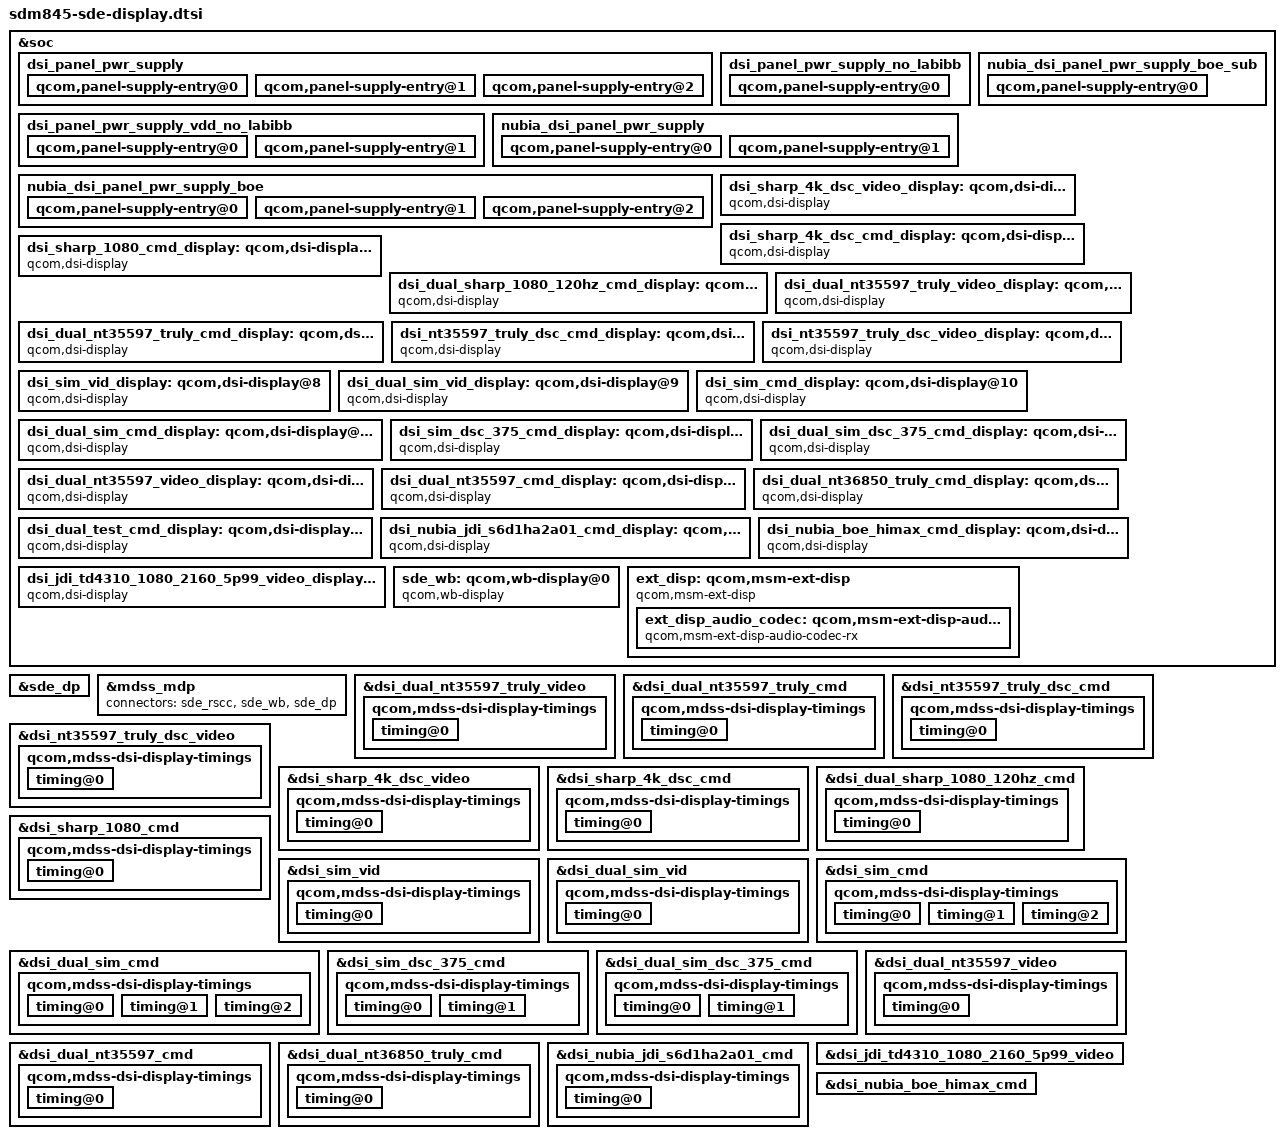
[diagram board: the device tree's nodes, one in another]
/* Copyright (c) 2016-2018, The Linux Foundation. All rights reserved.
 *
 * This program is free software; you can redistribute it and/or modify
 * it under the terms of the GNU General Public License version 2 and
 * only version 2 as published by the Free Software Foundation.
 *
 * This program is distributed in the hope that it will be useful,
 * but WITHOUT ANY WARRANTY; without even the implied warranty of
 * MERCHANTABILITY or FITNESS FOR A PARTICULAR PURPOSE.  See the
 * GNU General Public License for more details.
 */

#include "dsi-panel-sim-video.dtsi"
#include "dsi-panel-sim-cmd.dtsi"
#include "dsi-panel-sim-dsc375-cmd.dtsi"
#include "dsi-panel-sim-dualmipi-video.dtsi"
#include "dsi-panel-sim-dualmipi-cmd.dtsi"
#include "dsi-panel-sim-dualmipi-dsc375-cmd.dtsi"
#include "dsi-panel-sharp-dsc-4k-video.dtsi"
#include "dsi-panel-sharp-dsc-4k-cmd.dtsi"
#include "dsi-panel-nt35597-truly-dualmipi-wqxga-video.dtsi"
#include "dsi-panel-nt35597-truly-dualmipi-wqxga-cmd.dtsi"
#include "dsi-panel-nt35597-truly-dsc-wqxga-cmd.dtsi"
#include "dsi-panel-nt35597-truly-dsc-wqxga-video.dtsi"
#include "dsi-panel-sharp-1080p-cmd.dtsi"
#include "dsi-panel-sharp-dualmipi-1080p-120hz.dtsi"
#include "dsi-panel-s6e3ha3-amoled-dualmipi-wqhd-cmd.dtsi"
#include "dsi-panel-nt35597-dualmipi-wqxga-video.dtsi"
#include "dsi-panel-nt35597-dualmipi-wqxga-cmd.dtsi"
#include "dsi-panel-nt36850-truly-dualmipi-wqhd-cmd.dtsi"
#include "dsi-panel-test-dualmipi-oled-cmd.dtsi"
#include <dt-bindings/clock/mdss-10nm-pll-clk.h>
#include "../nubia/NX616J/dsi-panel-s6d1ha2a01-jdi-1080x2160-cmd.dtsi"
#include "../nubia/NX616J/dsi-panel-himax-boe-1080x2280-cmd.dtsi"
#include "../nubia/NX616J/nubia-jdi-td4310-1080-2160-5p99-video.dtsi"
&soc {
	dsi_panel_pwr_supply: dsi_panel_pwr_supply {
		#address-cells = <1>;
		#size-cells = <0>;

		qcom,panel-supply-entry@0 {
			reg = <0>;
			qcom,supply-name = "vddio";
			qcom,supply-min-voltage = <1800000>;
			qcom,supply-max-voltage = <1800000>;
			qcom,supply-enable-load = <62000>;
			qcom,supply-disable-load = <80>;
			qcom,supply-post-on-sleep = <20>;
		};

		qcom,panel-supply-entry@1 {
			reg = <1>;
			qcom,supply-name = "lab";
			qcom,supply-min-voltage = <4600000>;
			qcom,supply-max-voltage = <6000000>;
			qcom,supply-enable-load = <100000>;
			qcom,supply-disable-load = <100>;
		};

		qcom,panel-supply-entry@2 {
			reg = <2>;
			qcom,supply-name = "ibb";
			qcom,supply-min-voltage = <4600000>;
			qcom,supply-max-voltage = <6000000>;
			qcom,supply-enable-load = <100000>;
			qcom,supply-disable-load = <100>;
			qcom,supply-post-on-sleep = <20>;
		};
	};

	dsi_panel_pwr_supply_no_labibb: dsi_panel_pwr_supply_no_labibb {
		#address-cells = <1>;
		#size-cells = <0>;

		qcom,panel-supply-entry@0 {
			reg = <0>;
			qcom,supply-name = "vddio";
			qcom,supply-min-voltage = <1800000>;
			qcom,supply-max-voltage = <1800000>;
			qcom,supply-enable-load = <62000>;
			qcom,supply-disable-load = <80>;
			qcom,supply-post-on-sleep = <20>;
		};
	};

	dsi_panel_pwr_supply_vdd_no_labibb: dsi_panel_pwr_supply_vdd_no_labibb {
		#address-cells = <1>;
		#size-cells = <0>;

		qcom,panel-supply-entry@0 {
			reg = <0>;
			qcom,supply-name = "vddio";
			qcom,supply-min-voltage = <1800000>;
			qcom,supply-max-voltage = <1800000>;
			qcom,supply-enable-load = <62000>;
			qcom,supply-disable-load = <80>;
			qcom,supply-post-on-sleep = <20>;
		};

		qcom,panel-supply-entry@1 {
			reg = <1>;
			qcom,supply-name = "vdd";
			qcom,supply-min-voltage = <3000000>;
			qcom,supply-max-voltage = <3000000>;
			qcom,supply-enable-load = <857000>;
			qcom,supply-disable-load = <0>;
			qcom,supply-post-on-sleep = <0>;
		};
	};

	nubia_dsi_panel_pwr_supply: nubia_dsi_panel_pwr_supply {
			#address-cells = <1>;
			#size-cells = <0>;

			qcom,panel-supply-entry@0 {
				reg = <0>;
				qcom,supply-name = "lab";
				qcom,supply-min-voltage = <5400000>;
				qcom,supply-max-voltage = <5600000>;
				qcom,supply-enable-load = <100000>;
				qcom,supply-disable-load = <100>;
			};
			qcom,panel-supply-entry@1 {
				reg = <1>;
				qcom,supply-name = "ibb";
				qcom,supply-min-voltage = <5400000>;
				qcom,supply-max-voltage = <5600000>;
				qcom,supply-enable-load = <100000>;
				qcom,supply-disable-load = <100>;
			};
		};
//start :add the power of lcds for NX616J -------0330
	nubia_dsi_panel_pwr_supply_boe: nubia_dsi_panel_pwr_supply_boe {
			#address-cells = <1>;
			#size-cells = <0>;
		qcom,panel-supply-entry@0 {
			reg = <0>;
			qcom,supply-name = "vddio";
			qcom,supply-min-voltage = <1800000>;
			qcom,supply-max-voltage = <1800000>;
			qcom,supply-enable-load = <62000>;
			qcom,supply-disable-load = <80>;
			qcom,supply-post-on-sleep = <20>;
		};			
			qcom,panel-supply-entry@1 {
				reg = <1>;
				qcom,supply-name = "lab";
				qcom,supply-min-voltage = <5400000>;
				qcom,supply-max-voltage = <5600000>;
				qcom,supply-enable-load = <100000>;
				qcom,supply-disable-load = <100>;
			};
			qcom,panel-supply-entry@2 {
				reg = <2>;
				qcom,supply-name = "ibb";
				qcom,supply-min-voltage = <5400000>;
				qcom,supply-max-voltage = <5600000>;
				qcom,supply-enable-load = <100000>;
				qcom,supply-disable-load = <100>;
			};
		/*	
			qcom,panel-supply-entry@3 {
				reg = <3>;
				qcom,supply-name = "sub_lcd";
				qcom,supply-min-voltage = <3000000>;
				qcom,supply-max-voltage = <3000000>;
				qcom,supply-enable-load = <100000>;
				qcom,supply-disable-load = <100>;
			};*/
		};



	nubia_dsi_panel_pwr_supply_boe_sub: nubia_dsi_panel_pwr_supply_boe_sub {
			#address-cells = <1>;
			#size-cells = <0>;
			qcom,panel-supply-entry@0 {
				reg = <0>;
				qcom,supply-name = "sub_lcd";
				qcom,supply-min-voltage = <3000000>;
				qcom,supply-max-voltage = <3000000>;
				qcom,supply-enable-load = <100000>;
				qcom,supply-disable-load = <100>;
			};
		};
//End :add the power of lcds for NX616J -------0330

	dsi_sharp_4k_dsc_video_display: qcom,dsi-display@0 {
		compatible = "qcom,dsi-display";
		label = "dsi_sharp_4k_dsc_video_display";
		qcom,display-type = "primary";

		qcom,dsi-ctrl = <&mdss_dsi0 &mdss_dsi1>;
		qcom,dsi-phy = <&mdss_dsi_phy0 &mdss_dsi_phy1>;
		clocks = <&mdss_dsi0_pll BYTECLK_MUX_0_CLK>,
			<&mdss_dsi0_pll PCLK_MUX_0_CLK>;
		clock-names = "src_byte_clk", "src_pixel_clk";

		pinctrl-names = "panel_active", "panel_suspend";
		pinctrl-0 = <&sde_dsi_active &sde_te_active>;
		pinctrl-1 = <&sde_dsi_suspend &sde_te_suspend>;
		qcom,platform-te-gpio = <&tlmm 10 0>;
		qcom,platform-reset-gpio = <&tlmm 6 0>;
		qcom,panel-mode-gpio = <&tlmm 52 0>;

		qcom,dsi-panel = <&dsi_sharp_4k_dsc_video>;
		vddio-supply = <&pm8998_l14>;
		lab-supply = <&lab_regulator>;
		ibb-supply = <&ibb_regulator>;
	};

	dsi_sharp_4k_dsc_cmd_display: qcom,dsi-display@1 {
		compatible = "qcom,dsi-display";
		label = "dsi_sharp_4k_dsc_cmd_display";
		qcom,display-type = "primary";

		qcom,dsi-ctrl = <&mdss_dsi0 &mdss_dsi1>;
		qcom,dsi-phy = <&mdss_dsi_phy0 &mdss_dsi_phy1>;
		clocks = <&mdss_dsi0_pll BYTECLK_MUX_0_CLK>,
			<&mdss_dsi0_pll PCLK_MUX_0_CLK>;
		clock-names = "src_byte_clk", "src_pixel_clk";

		pinctrl-names = "panel_active", "panel_suspend";
		pinctrl-0 = <&sde_dsi_active &sde_te_active>;
		pinctrl-1 = <&sde_dsi_suspend &sde_te_suspend>;
		qcom,platform-te-gpio = <&tlmm 10 0>;
		qcom,platform-reset-gpio = <&tlmm 6 0>;
		qcom,panel-mode-gpio = <&tlmm 52 0>;

		qcom,dsi-panel = <&dsi_sharp_4k_dsc_cmd>;
		vddio-supply = <&pm8998_l14>;
		lab-supply = <&lab_regulator>;
		ibb-supply = <&ibb_regulator>;
	};

	dsi_sharp_1080_cmd_display: qcom,dsi-display@2 {
		compatible = "qcom,dsi-display";
		label = "dsi_sharp_1080_cmd_display";
		qcom,display-type = "primary";

		qcom,dsi-ctrl = <&mdss_dsi0>;
		qcom,dsi-phy = <&mdss_dsi_phy0>;
		clocks = <&mdss_dsi0_pll BYTECLK_MUX_0_CLK>,
			<&mdss_dsi0_pll PCLK_MUX_0_CLK>;
		clock-names = "src_byte_clk", "src_pixel_clk";

		pinctrl-names = "panel_active", "panel_suspend";
		pinctrl-0 = <&sde_dsi_active &sde_te_active>;
		pinctrl-1 = <&sde_dsi_suspend &sde_te_suspend>;
		qcom,platform-te-gpio = <&tlmm 10 0>;
		qcom,platform-reset-gpio = <&tlmm 6 0>;
		qcom,panel-mode-gpio = <&tlmm 52 0>;

		qcom,dsi-panel = <&dsi_sharp_1080_cmd>;
		vddio-supply = <&pm8998_l14>;
		lab-supply = <&lab_regulator>;
		ibb-supply = <&ibb_regulator>;
	};

	dsi_dual_sharp_1080_120hz_cmd_display: qcom,dsi-display@3 {
		compatible = "qcom,dsi-display";
		label = "dsi_dual_sharp_1080_120hz_cmd_display";
		qcom,display-type = "primary";

		qcom,dsi-ctrl = <&mdss_dsi0 &mdss_dsi1>;
		qcom,dsi-phy = <&mdss_dsi_phy0 &mdss_dsi_phy1>;
		clocks = <&mdss_dsi0_pll BYTECLK_MUX_0_CLK>,
			<&mdss_dsi0_pll PCLK_MUX_0_CLK>;
		clock-names = "src_byte_clk", "src_pixel_clk";

		pinctrl-names = "panel_active", "panel_suspend";
		pinctrl-0 = <&sde_dsi_active &sde_te_active>;
		pinctrl-1 = <&sde_dsi_suspend &sde_te_suspend>;
		qcom,platform-te-gpio = <&tlmm 10 0>;
		qcom,platform-reset-gpio = <&tlmm 6 0>;
		qcom,panel-mode-gpio = <&tlmm 52 0>;

		qcom,dsi-panel = <&dsi_dual_sharp_1080_120hz_cmd>;
		vddio-supply = <&pm8998_l14>;
		lab-supply = <&lab_regulator>;
		ibb-supply = <&ibb_regulator>;
	};

	dsi_dual_nt35597_truly_video_display: qcom,dsi-display@4 {
		compatible = "qcom,dsi-display";
		label = "dsi_dual_nt35597_truly_video_display";
		qcom,display-type = "primary";

		qcom,dsi-ctrl = <&mdss_dsi0 &mdss_dsi1>;
		qcom,dsi-phy = <&mdss_dsi_phy0 &mdss_dsi_phy1>;
		clocks = <&mdss_dsi0_pll BYTECLK_MUX_0_CLK>,
			<&mdss_dsi0_pll PCLK_MUX_0_CLK>;
		clock-names = "src_byte_clk", "src_pixel_clk";

		pinctrl-names = "panel_active", "panel_suspend";
		pinctrl-0 = <&sde_dsi_active &sde_te_active>;
		pinctrl-1 = <&sde_dsi_suspend &sde_te_suspend>;
		qcom,platform-reset-gpio = <&tlmm 6 0>;
		qcom,panel-mode-gpio = <&tlmm 52 0>;

		qcom,dsi-panel = <&dsi_dual_nt35597_truly_video>;
		vddio-supply = <&pm8998_l14>;
		lab-supply = <&lab_regulator>;
		ibb-supply = <&ibb_regulator>;
	};

	dsi_dual_nt35597_truly_cmd_display: qcom,dsi-display@5 {
		compatible = "qcom,dsi-display";
		label = "dsi_dual_nt35597_truly_cmd_display";
		qcom,display-type = "primary";

		qcom,dsi-ctrl = <&mdss_dsi0 &mdss_dsi1>;
		qcom,dsi-phy = <&mdss_dsi_phy0 &mdss_dsi_phy1>;
		clocks = <&mdss_dsi0_pll BYTECLK_MUX_0_CLK>,
			<&mdss_dsi0_pll PCLK_MUX_0_CLK>;
		clock-names = "src_byte_clk", "src_pixel_clk";

		pinctrl-names = "panel_active", "panel_suspend";
		pinctrl-0 = <&sde_dsi_active &sde_te_active>;
		pinctrl-1 = <&sde_dsi_suspend &sde_te_suspend>;
		qcom,platform-te-gpio = <&tlmm 10 0>;
		qcom,platform-reset-gpio = <&tlmm 6 0>;
		qcom,panel-mode-gpio = <&tlmm 52 0>;

		qcom,dsi-panel = <&dsi_dual_nt35597_truly_cmd>;
		vddio-supply = <&pm8998_l14>;
		lab-supply = <&lab_regulator>;
		ibb-supply = <&ibb_regulator>;
	};

	dsi_nt35597_truly_dsc_cmd_display: qcom,dsi-display@6 {
		compatible = "qcom,dsi-display";
		label = "dsi_nt35597_truly_dsc_cmd_display";
		qcom,display-type = "primary";

		qcom,dsi-ctrl = <&mdss_dsi1>;
		qcom,dsi-phy = <&mdss_dsi_phy1>;
		clocks = <&mdss_dsi1_pll BYTECLK_MUX_1_CLK>,
			<&mdss_dsi1_pll PCLK_MUX_1_CLK>;
		clock-names = "src_byte_clk", "src_pixel_clk";

		pinctrl-names = "panel_active", "panel_suspend";
		pinctrl-0 = <&sde_dsi_active &sde_te_active>;
		pinctrl-1 = <&sde_dsi_suspend &sde_te_suspend>;
		qcom,platform-te-gpio = <&tlmm 10 0>;
		qcom,platform-reset-gpio = <&tlmm 6 0>;
		qcom,panel-mode-gpio = <&tlmm 52 0>;

		qcom,dsi-panel = <&dsi_nt35597_truly_dsc_cmd>;
		vddio-supply = <&pm8998_l14>;
		lab-supply = <&lab_regulator>;
		ibb-supply = <&ibb_regulator>;
	};

	dsi_nt35597_truly_dsc_video_display: qcom,dsi-display@7 {
		compatible = "qcom,dsi-display";
		label = "dsi_nt35597_truly_dsc_video_display";
		qcom,display-type = "primary";

		qcom,dsi-ctrl = <&mdss_dsi1>;
		qcom,dsi-phy = <&mdss_dsi_phy1>;
		clocks = <&mdss_dsi1_pll BYTECLK_MUX_1_CLK>,
			<&mdss_dsi1_pll PCLK_MUX_1_CLK>;
		clock-names = "src_byte_clk", "src_pixel_clk";

		pinctrl-names = "panel_active", "panel_suspend";
		pinctrl-0 = <&sde_dsi_active &sde_te_active>;
		pinctrl-1 = <&sde_dsi_suspend &sde_te_suspend>;
		qcom,platform-te-gpio = <&tlmm 10 0>;
		qcom,platform-reset-gpio = <&tlmm 6 0>;
		qcom,panel-mode-gpio = <&tlmm 52 0>;

		qcom,dsi-panel = <&dsi_nt35597_truly_dsc_video>;
		vddio-supply = <&pm8998_l14>;
		lab-supply = <&lab_regulator>;
		ibb-supply = <&ibb_regulator>;
	};

	dsi_sim_vid_display: qcom,dsi-display@8 {
		compatible = "qcom,dsi-display";
		label = "dsi_sim_vid_display";
		qcom,display-type = "primary";

		qcom,dsi-ctrl = <&mdss_dsi0>;
		qcom,dsi-phy = <&mdss_dsi_phy0>;
		clocks = <&mdss_dsi0_pll BYTECLK_MUX_0_CLK>,
			<&mdss_dsi0_pll PCLK_MUX_0_CLK>;
		clock-names = "src_byte_clk", "src_pixel_clk";

		pinctrl-names = "panel_active", "panel_suspend";
		pinctrl-0 = <&sde_dsi_active &sde_te_active>;
		pinctrl-1 = <&sde_dsi_suspend &sde_te_suspend>;

		qcom,dsi-panel = <&dsi_sim_vid>;
	};

	dsi_dual_sim_vid_display: qcom,dsi-display@9 {
		compatible = "qcom,dsi-display";
		label = "dsi_dual_sim_vid_display";
		qcom,display-type = "primary";

		qcom,dsi-ctrl = <&mdss_dsi0 &mdss_dsi1>;
		qcom,dsi-phy = <&mdss_dsi_phy0 &mdss_dsi_phy1>;
		clocks = <&mdss_dsi0_pll BYTECLK_MUX_0_CLK>,
			<&mdss_dsi0_pll PCLK_MUX_0_CLK>;
		clock-names = "src_byte_clk", "src_pixel_clk";

		pinctrl-names = "panel_active", "panel_suspend";
		pinctrl-0 = <&sde_dsi_active &sde_te_active>;
		pinctrl-1 = <&sde_dsi_suspend &sde_te_suspend>;

		qcom,dsi-panel = <&dsi_dual_sim_vid>;
	};

	dsi_sim_cmd_display: qcom,dsi-display@10 {
		compatible = "qcom,dsi-display";
		label = "dsi_sim_cmd_display";
		qcom,display-type = "primary";

		qcom,dsi-ctrl = <&mdss_dsi0>;
		qcom,dsi-phy = <&mdss_dsi_phy0>;
		clocks = <&mdss_dsi0_pll BYTECLK_MUX_0_CLK>,
			<&mdss_dsi0_pll PCLK_MUX_0_CLK>;
		clock-names = "src_byte_clk", "src_pixel_clk";

		pinctrl-names = "panel_active", "panel_suspend";
		pinctrl-0 = <&sde_dsi_active &sde_te_active>;
		pinctrl-1 = <&sde_dsi_suspend &sde_te_suspend>;

		qcom,dsi-panel = <&dsi_sim_cmd>;
	};

	dsi_dual_sim_cmd_display: qcom,dsi-display@11 {
		compatible = "qcom,dsi-display";
		label = "dsi_dual_sim_cmd_display";
		qcom,display-type = "primary";

		qcom,dsi-ctrl = <&mdss_dsi0 &mdss_dsi1>;
		qcom,dsi-phy = <&mdss_dsi_phy0 &mdss_dsi_phy1>;
		clocks = <&mdss_dsi0_pll BYTECLK_MUX_0_CLK>,
			<&mdss_dsi0_pll PCLK_MUX_0_CLK>;
		clock-names = "src_byte_clk", "src_pixel_clk";

		pinctrl-names = "panel_active", "panel_suspend";
		pinctrl-0 = <&sde_dsi_active &sde_te_active>;
		pinctrl-1 = <&sde_dsi_suspend &sde_te_suspend>;

		qcom,dsi-panel = <&dsi_dual_sim_cmd>;
	};

	dsi_sim_dsc_375_cmd_display: qcom,dsi-display@12 {
		compatible = "qcom,dsi-display";
		label = "dsi_sim_dsc_375_cmd_display";
		qcom,display-type = "primary";

		qcom,dsi-ctrl = <&mdss_dsi0>;
		qcom,dsi-phy = <&mdss_dsi_phy0>;
		clocks = <&mdss_dsi0_pll BYTECLK_MUX_0_CLK>,
			<&mdss_dsi0_pll PCLK_MUX_0_CLK>;
		clock-names = "src_byte_clk", "src_pixel_clk";

		pinctrl-names = "panel_active", "panel_suspend";
		pinctrl-0 = <&sde_dsi_active &sde_te_active>;
		pinctrl-1 = <&sde_dsi_suspend &sde_te_suspend>;

		qcom,dsi-panel = <&dsi_sim_dsc_375_cmd>;
	};

	dsi_dual_sim_dsc_375_cmd_display: qcom,dsi-display@13 {
		compatible = "qcom,dsi-display";
		label = "dsi_dual_sim_dsc_375_cmd_display";
		qcom,display-type = "primary";

		qcom,dsi-ctrl = <&mdss_dsi0 &mdss_dsi1>;
		qcom,dsi-phy = <&mdss_dsi_phy0 &mdss_dsi_phy1>;
		clocks = <&mdss_dsi0_pll BYTECLK_MUX_0_CLK>,
			<&mdss_dsi0_pll PCLK_MUX_0_CLK>;
		clock-names = "src_byte_clk", "src_pixel_clk";

		pinctrl-names = "panel_active", "panel_suspend";
		pinctrl-0 = <&sde_dsi_active &sde_te_active>;
		pinctrl-1 = <&sde_dsi_suspend &sde_te_suspend>;

		qcom,dsi-panel = <&dsi_dual_sim_dsc_375_cmd>;
	};

	dsi_dual_nt35597_video_display: qcom,dsi-display@14 {
		compatible = "qcom,dsi-display";
		label = "dsi_dual_nt35597_video_display";
		qcom,display-type = "primary";

		qcom,dsi-ctrl = <&mdss_dsi0 &mdss_dsi1>;
		qcom,dsi-phy = <&mdss_dsi_phy0 &mdss_dsi_phy1>;
		clocks = <&mdss_dsi0_pll BYTECLK_MUX_0_CLK>,
		       <&mdss_dsi0_pll PCLK_MUX_0_CLK>;
		clock-names = "src_byte_clk", "src_pixel_clk";

		pinctrl-names = "panel_active", "panel_suspend";
		pinctrl-0 = <&sde_dsi_active &sde_te_active>;
		pinctrl-1 = <&sde_dsi_suspend &sde_te_suspend>;
		qcom,platform-reset-gpio = <&tlmm 6 0>;
		qcom,panel-mode-gpio = <&tlmm 52 0>;

		qcom,dsi-panel = <&dsi_dual_nt35597_video>;
		vddio-supply = <&pm8998_l14>;
		lab-supply = <&lab_regulator>;
		ibb-supply = <&ibb_regulator>;
	};


	dsi_dual_nt35597_cmd_display: qcom,dsi-display@15 {
		compatible = "qcom,dsi-display";
		label = "dsi_dual_nt35597_cmd_display";
		qcom,display-type = "primary";

		qcom,dsi-ctrl = <&mdss_dsi0 &mdss_dsi1>;
		qcom,dsi-phy = <&mdss_dsi_phy0 &mdss_dsi_phy1>;
		clocks = <&mdss_dsi0_pll BYTECLK_MUX_0_CLK>,
		       <&mdss_dsi0_pll PCLK_MUX_0_CLK>;
		clock-names = "src_byte_clk", "src_pixel_clk";

		pinctrl-names = "panel_active", "panel_suspend";
		pinctrl-0 = <&sde_dsi_active &sde_te_active>;
		pinctrl-1 = <&sde_dsi_suspend &sde_te_suspend>;
		qcom,platform-te-gpio = <&tlmm 10 0>;
		qcom,platform-reset-gpio = <&tlmm 6 0>;
		qcom,panel-mode-gpio = <&tlmm 52 0>;

		qcom,dsi-panel = <&dsi_dual_nt35597_cmd>;
		vddio-supply = <&pm8998_l14>;
		lab-supply = <&lab_regulator>;
		ibb-supply = <&ibb_regulator>;
	};

	dsi_dual_nt36850_truly_cmd_display: qcom,dsi-display@16 {
		compatible = "qcom,dsi-display";
		label = "dsi_dual_nt36850_truly_cmd_display";
		qcom,display-type = "primary";

		qcom,dsi-ctrl = <&mdss_dsi0 &mdss_dsi1>;
		qcom,dsi-phy = <&mdss_dsi_phy0 &mdss_dsi_phy1>;
		clocks = <&mdss_dsi0_pll BYTECLK_MUX_0_CLK>,
			<&mdss_dsi0_pll PCLK_MUX_0_CLK>;
		clock-names = "src_byte_clk", "src_pixel_clk";

		pinctrl-names = "panel_active", "panel_suspend";
		pinctrl-0 = <&sde_dsi_active &sde_te_active>;
		pinctrl-1 = <&sde_dsi_suspend &sde_te_suspend>;
		qcom,platform-te-gpio = <&tlmm 10 0>;
		qcom,platform-reset-gpio = <&tlmm 6 0>;
		qcom,panel-mode-gpio = <&tlmm 52 0>;

		qcom,dsi-panel = <&dsi_dual_nt36850_truly_cmd>;
		vddio-supply = <&pm8998_l14>;
		lab-supply = <&lab_regulator>;
		ibb-supply = <&ibb_regulator>;
	};
        dsi_dual_test_cmd_display: qcom,dsi-display@17 {
                compatible = "qcom,dsi-display";
                label = "dsi_dual_test_cmd";
                qcom,display-type = "primary";

                qcom,dsi-ctrl = <&mdss_dsi0 &mdss_dsi1>;
                qcom,dsi-phy = <&mdss_dsi_phy0 &mdss_dsi_phy1>;
                clocks = <&mdss_dsi0_pll BYTECLK_MUX_0_CLK>,
                                <&mdss_dsi0_pll PCLK_MUX_0_CLK>;
                clock-names = "src_byte_clk", "src_pixel_clk";

                pinctrl-names = "panel_active", "panel_suspend";
                pinctrl-0 = <&sde_dsi_active &sde_te_active>;
                pinctrl-1 = <&sde_dsi_suspend &sde_te_suspend>;
                qcom,platform-te-gpio = <&tlmm 10 0>;
                qcom,platform-reset-gpio = <&tlmm 6 0>;
                qcom,panel-mode-gpio = <&tlmm 52 0>;

                qcom,dsi-panel = <&dsi_dual_test_cmd>;
                vddio-supply = <&pm8998_l14>;
                lab-supply = <&lab_regulator>;
                ibb-supply = <&ibb_regulator>;
                oled-vdda-supply = <&pm8998_l22>;
        };

	dsi_nubia_jdi_s6d1ha2a01_cmd_display: qcom,dsi-display@18 {
		qcom,dsi-display-active;
		compatible = "qcom,dsi-display";
		label = "dsi_nubia_jdi_s6d1ha2a01_cmd_display";
		qcom,display-type = "primary";

		qcom,dsi-ctrl = <&mdss_dsi0>;
		qcom,dsi-phy = <&mdss_dsi_phy0>;
		clocks = <&mdss_dsi0_pll BYTECLK_MUX_0_CLK>,
			<&mdss_dsi0_pll PCLK_MUX_0_CLK>;
		clock-names = "src_byte_clk", "src_pixel_clk";

		pinctrl-names = "panel_active", "panel_suspend";
		pinctrl-0 = <&sde_dsi_active &sde_te_active>;
		pinctrl-1 = <&sde_dsi_suspend &sde_te_suspend>;
		qcom,platform-te-gpio = <&tlmm 10 0>;
		qcom,platform-reset-gpio = <&tlmm 6 0>;
		qcom,panel-mode-gpio = <&tlmm 32 0>;

		qcom,dsi-panel = <&dsi_nubia_jdi_s6d1ha2a01_cmd>;
		lab-supply = <&lab_regulator>;
		ibb-supply = <&ibb_regulator>;

	};

//start : add for NX616J lcd

	dsi_nubia_boe_himax_cmd_display: qcom,dsi-display@19 {
		compatible = "qcom,dsi-display";
		label = "dsi_nubia_boe_himax_cmd_display";
		qcom,display-type = "primary";

		qcom,dsi-ctrl = <&mdss_dsi0>;
		qcom,dsi-phy = <&mdss_dsi_phy0>;
		clocks = <&mdss_dsi0_pll BYTECLK_MUX_0_CLK>,
			<&mdss_dsi0_pll PCLK_MUX_0_CLK>;
		clock-names = "src_byte_clk", "src_pixel_clk";

		pinctrl-names = "panel_active", "panel_suspend";
		pinctrl-0 = <&sde_dsi_active &sde_te_active>;
		pinctrl-1 = <&sde_dsi_suspend &sde_te_suspend>;
		qcom,platform-te-gpio = <&tlmm 10 0>;
		qcom,platform-reset-gpio = <&tlmm 6 0>;
		qcom,panel-mode-gpio = <&tlmm 32 0>;

		qcom,dsi-panel = <&dsi_nubia_boe_himax_cmd>;
		lab-supply = <&lab_regulator>;
		ibb-supply = <&ibb_regulator>;
		vddio-supply = <&pm8998_l14>;
		sub_lcd-supply = <&pm8998_l22>;

	};

        dsi_jdi_td4310_1080_2160_5p99_video_display: qcom,dsi-display@20 {
                compatible = "qcom,dsi-display";
                label = "dsi_jdi_td4310_1080_2160_5p99_video_display";
                qcom,display-type = "primary";

                qcom,dsi-ctrl = <&mdss_dsi0>;
                qcom,dsi-phy = <&mdss_dsi_phy0>;
                clocks = <&mdss_dsi0_pll BYTECLK_MUX_0_CLK>,
                        <&mdss_dsi0_pll PCLK_MUX_0_CLK>;
                clock-names = "src_byte_clk", "src_pixel_clk";

                pinctrl-names = "panel_active", "panel_suspend";
                pinctrl-0 = <&sde_dsi_active &sde_te_active>;
                pinctrl-1 = <&sde_dsi_suspend &sde_te_suspend>;
                qcom,platform-reset-gpio = <&tlmm 6 0>;
                qcom,panel-mode-gpio = <&tlmm 32 0>;

                qcom,dsi-panel = <&dsi_jdi_td4310_1080_2160_5p99_video>;
                vddio-supply = <&pm8998_l14>;
                lab-supply = <&lab_regulator>;
                ibb-supply = <&ibb_regulator>;
        };


//end : add for NX616J lcd
	sde_wb: qcom,wb-display@0 {
		compatible = "qcom,wb-display";
		cell-index = <0>;
		label = "wb_display";
	};

	ext_disp: qcom,msm-ext-disp {
		compatible = "qcom,msm-ext-disp";

		ext_disp_audio_codec: qcom,msm-ext-disp-audio-codec-rx {
			compatible = "qcom,msm-ext-disp-audio-codec-rx";
		};
	};
};

&sde_dp {
	qcom,dp-usbpd-detection = <&pmi8998_pdphy>;
	qcom,ext-disp = <&ext_disp>;
/* gpio43 and gpio 51 is used by audio,gio 2 and gpio 3 connect nothing for gpio request crash */
	pinctrl-names = "mdss_dp_active", "mdss_dp_sleep";
	pinctrl-0 = <&sde_dp_aux_active &sde_dp_usbplug_cc_active>;
	pinctrl-1 = <&sde_dp_aux_suspend &sde_dp_usbplug_cc_suspend>;
	qcom,aux-en-gpio = <&tlmm 2 0>;
	qcom,aux-sel-gpio = <&tlmm 3 0>;
	qcom,usbplug-cc-gpio = <&tlmm 38 0>;
};

&mdss_mdp {
	connectors = <&sde_rscc &sde_wb &sde_dp>;
};

&dsi_dual_nt35597_truly_video {
	qcom,mdss-dsi-t-clk-post = <0x0D>;
	qcom,mdss-dsi-t-clk-pre = <0x2D>;
	qcom,esd-check-enabled;
	qcom,mdss-dsi-panel-status-check-mode = "reg_read";
	qcom,mdss-dsi-panel-status-command = [06 01 00 01 00 00 01 0a];
	qcom,mdss-dsi-panel-status-command-state = "dsi_hs_mode";
	qcom,mdss-dsi-panel-status-value = <0x9c>;
	qcom,mdss-dsi-panel-on-check-value = <0x9c>;
	qcom,mdss-dsi-panel-status-read-length = <1>;
	qcom,mdss-dsi-display-timings {
		timing@0{
			qcom,mdss-dsi-panel-phy-timings = [00 1c 07 07 23 21 07
				07 05 03 04 00];
			qcom,display-topology = <2 0 2>,
						<1 0 2>;
			qcom,default-topology-index = <0>;
		};
	};
};

&dsi_dual_nt35597_truly_cmd {
	qcom,mdss-dsi-t-clk-post = <0x0D>;
	qcom,mdss-dsi-t-clk-pre = <0x2D>;
	qcom,esd-check-enabled;
	qcom,mdss-dsi-panel-status-check-mode = "reg_read";
	qcom,mdss-dsi-panel-status-command = [06 01 00 01 00 00 01 0a];
	qcom,mdss-dsi-panel-status-command-state = "dsi_hs_mode";
	qcom,mdss-dsi-panel-status-value = <0x9c>;
	qcom,mdss-dsi-panel-on-check-value = <0x9c>;
	qcom,mdss-dsi-panel-status-read-length = <1>;
	qcom,mdss-dsi-display-timings {
		timing@0{
			qcom,mdss-dsi-panel-phy-timings = [00 1c 07 07 23 21 07
				07 05 03 04 00];
			qcom,display-topology = <2 0 2>,
						<1 0 2>;
			qcom,default-topology-index = <0>;
		};
	};
};

&dsi_nt35597_truly_dsc_cmd {
	qcom,mdss-dsi-t-clk-post = <0x0b>;
	qcom,mdss-dsi-t-clk-pre = <0x23>;
	qcom,ulps-enabled;
	qcom,esd-check-enabled;
	qcom,mdss-dsi-panel-status-check-mode = "reg_read";
	qcom,mdss-dsi-panel-status-command = [06 01 00 01 00 00 01 0a];
	qcom,mdss-dsi-panel-status-command-state = "dsi_hs_mode";
	qcom,mdss-dsi-panel-status-value = <0x9c>;
	qcom,mdss-dsi-panel-on-check-value = <0x9c>;
	qcom,mdss-dsi-panel-status-read-length = <1>;
	qcom,mdss-dsi-display-timings {
		timing@0{
			qcom,mdss-dsi-panel-phy-timings = [00 15 05 05 20 1f 05
				05 03 03 04 00];
			qcom,display-topology = <1 1 1>,
						<2 2 1>, /* dsc merge */
						<2 1 1>; /* 3d mux */
			qcom,default-topology-index = <1>;
		};
	};
};

&dsi_nt35597_truly_dsc_video {
	qcom,mdss-dsi-t-clk-post = <0x0b>;
	qcom,mdss-dsi-t-clk-pre = <0x23>;
	qcom,esd-check-enabled;
	qcom,mdss-dsi-panel-status-check-mode = "reg_read";
	qcom,mdss-dsi-panel-status-command = [06 01 00 01 00 00 01 0a];
	qcom,mdss-dsi-panel-status-command-state = "dsi_hs_mode";
	qcom,mdss-dsi-panel-status-value = <0x9c>;
	qcom,mdss-dsi-panel-on-check-value = <0x9c>;
	qcom,mdss-dsi-panel-status-read-length = <1>;
	qcom,mdss-dsi-display-timings {
		timing@0{
			qcom,mdss-dsi-panel-phy-timings = [00 15 05 05 20 1f 05
				04 03 03 04 00];
			qcom,display-topology = <1 1 1>,
						<2 2 1>, /* dsc merge */
						<2 1 1>; /* 3d mux */
			qcom,default-topology-index = <1>;
		};
	};
};

&dsi_sharp_4k_dsc_video {
	qcom,mdss-dsi-t-clk-post = <0x0c>;
	qcom,mdss-dsi-t-clk-pre = <0x27>;
	qcom,mdss-dsi-display-timings {
		timing@0{
			qcom,mdss-dsi-panel-phy-timings = [00 18 06 06 21 20 06
				06 04 03 04 00];
			qcom,display-topology = <2 2 2>;
			qcom,default-topology-index = <0>;
		};
	};
};

&dsi_sharp_4k_dsc_cmd {
	qcom,mdss-dsi-t-clk-post = <0x0c>;
	qcom,mdss-dsi-t-clk-pre = <0x27>;
	qcom,mdss-dsi-display-timings {
		timing@0{
			qcom,mdss-dsi-panel-phy-timings = [00 18 06 06 21 20 06
				06 04 03 04 00];
			qcom,display-topology = <2 2 2>;
			qcom,default-topology-index = <0>;
		};
	};
};

&dsi_dual_sharp_1080_120hz_cmd {
	qcom,mdss-dsi-t-clk-post = <0x0f>;
	qcom,mdss-dsi-t-clk-pre = <0x36>;
	qcom,mdss-dsi-display-timings {
		timing@0{
			qcom,mdss-dsi-panel-phy-timings = [00 24 09 09 26 24 09
				09 06 03 04 00];
			qcom,display-topology = <2 0 2>,
						<1 0 2>;
			qcom,default-topology-index = <0>;
		};
	};
};

&dsi_sharp_1080_cmd {
	qcom,mdss-dsi-t-clk-post = <0x0c>;
	qcom,mdss-dsi-t-clk-pre = <0x29>;
	qcom,mdss-dsi-display-timings {
		timing@0{
			qcom,mdss-dsi-panel-phy-timings = [00 1E 08 08 24 22 08
				08 05 03 04 00];
			qcom,mdss-dsi-panel-clockrate = <900000000>;
			qcom,display-topology = <1 0 1>;
			qcom,default-topology-index = <0>;
		};
	};
};

&dsi_sim_vid {
	qcom,mdss-dsi-t-clk-post = <0x0d>;
	qcom,mdss-dsi-t-clk-pre = <0x2d>;
	qcom,mdss-dsi-display-timings {
		timing@0{
			qcom,mdss-dsi-panel-phy-timings = [00 1c 07 07 23 21 07
				07 05 03 04 00];
			qcom,display-topology = <1 0 1>,
						<2 0 1>;
			qcom,default-topology-index = <0>;
		};
	};
};

&dsi_dual_sim_vid {
	qcom,mdss-dsi-t-clk-post = <0x0d>;
	qcom,mdss-dsi-t-clk-pre = <0x2d>;
	qcom,mdss-dsi-display-timings {
		timing@0{
			qcom,mdss-dsi-panel-phy-timings = [00 1c 07 07 23 21 07
				07 05 03 04 00];
			qcom,display-topology = <2 0 2>,
						<1 0 2>;
			qcom,default-topology-index = <0>;
		};
	};
};

&dsi_sim_cmd {
	qcom,mdss-dsi-t-clk-post = <0x0c>;
	qcom,mdss-dsi-t-clk-pre = <0x29>;
	qcom,mdss-dsi-display-timings {
		timing@0{
			qcom,display-topology = <1 0 1>,
						<2 2 1>;
			qcom,default-topology-index = <1>;
			qcom,panel-roi-alignment = <720 40 720 40 720 40>;
			qcom,partial-update-enabled = "single_roi";
			qcom,mdss-dsi-panel-phy-timings = [00 1a 06 06 22 20 07
				07 04 03 04 00];
		};
		timing@1{
			qcom,display-topology = <1 0 1>,
						<2 2 1>;
			qcom,default-topology-index = <1>;
			qcom,panel-roi-alignment = <540 40 540 40 540 40>;
			qcom,partial-update-enabled = "single_roi";
			qcom,mdss-dsi-panel-phy-timings = [00 1a 06 06 22 20 07
				07 04 03 04 00];
		};
		timing@2{
			qcom,display-topology = <1 0 1>,
						<2 2 1>;
			qcom,default-topology-index = <1>;
			qcom,panel-roi-alignment = <360 40 360 40 360 40>;
			qcom,partial-update-enabled = "single_roi";
			qcom,mdss-dsi-panel-phy-timings = [00 1a 06 06 22 20 07
				07 04 03 04 00];
		};
	};
};

&dsi_dual_sim_cmd {
	qcom,mdss-dsi-t-clk-post = <0x0d>;
	qcom,mdss-dsi-t-clk-pre = <0x2d>;
	qcom,mdss-dsi-display-timings {
		timing@0{
			qcom,mdss-dsi-panel-phy-timings = [00 24 09 09 26 24 09
				09 06 03 04 00];
			qcom,display-topology = <2 0 2>;
			qcom,default-topology-index = <0>;
		};
		timing@1{
			qcom,mdss-dsi-panel-phy-timings = [00 30 0c 0d 2a 27 0c
				0d 09 03 04 00];
			qcom,display-topology = <2 0 2>,
						<1 0 2>;
			qcom,default-topology-index = <0>;
		};
		timing@2{
			qcom,mdss-dsi-panel-phy-timings = [00 18 06 06 21 20 06
				06 04 03 04 00];
			qcom,display-topology = <2 0 2>;
			qcom,default-topology-index = <0>;
		};
	};
};

&dsi_sim_dsc_375_cmd {
	qcom,mdss-dsi-t-clk-post = <0x0d>;
	qcom,mdss-dsi-t-clk-pre = <0x2d>;
	qcom,mdss-dsi-display-timings {
		timing@0 { /* 1080p */
			qcom,mdss-dsi-panel-phy-timings = [00 1A 06 06 22 20 07
				07 04 03 04 00];
			qcom,display-topology = <1 1 1>;
			qcom,default-topology-index = <0>;
		};
		timing@1 { /* qhd */
			qcom,mdss-dsi-panel-phy-timings = [00 15 05 05 20 1f 05
				05 03 03 04 00];
			qcom,display-topology = <1 1 1>,
						<2 2 1>, /* dsc merge */
						<2 1 1>; /* 3d mux */
			qcom,default-topology-index = <0>;
		};
	};
};

&dsi_dual_sim_dsc_375_cmd {
	qcom,mdss-dsi-t-clk-post = <0x0d>;
	qcom,mdss-dsi-t-clk-pre = <0x2d>;
	qcom,mdss-dsi-display-timings {
		timing@0 { /* qhd */
			qcom,mdss-dsi-panel-phy-timings = [00 1c 07 07 23 21 07
				07 05 03 04 00];
			qcom,display-topology = <2 2 2>;
			qcom,default-topology-index = <0>;
		};
		timing@1 { /* 4k */
			qcom,mdss-dsi-panel-phy-timings = [00 18 06 06 21 20 06
				06 04 03 04 00];
			qcom,display-topology = <2 2 2>;
			qcom,default-topology-index = <0>;
		};
	};
};

&dsi_dual_nt35597_video {
	qcom,mdss-dsi-t-clk-post = <0x0d>;
	qcom,mdss-dsi-t-clk-pre = <0x2d>;
	qcom,mdss-dsi-display-timings {
		 timing@0 {
			qcom,mdss-dsi-panel-timings = [00 1c 08 07 23 22 07 07
				05 03 04 00];
			qcom,display-topology = <2 0 2>,
						<1 0 2>;
			qcom,default-topology-index = <0>;
		};
	};
};

&dsi_dual_nt35597_cmd {
	qcom,mdss-dsi-t-clk-post = <0x0d>;
	qcom,mdss-dsi-t-clk-pre = <0x2d>;
	qcom,mdss-dsi-display-timings {
		 timing@0 {
			qcom,mdss-dsi-panel-timings = [00 1c 08 07 23 22 07 07
				05 03 04 00];
			qcom,display-topology = <2 0 2>,
						<1 0 2>;
			qcom,default-topology-index = <0>;
		};
	};
};

&dsi_dual_nt36850_truly_cmd {
	qcom,mdss-dsi-t-clk-post = <0x0E>;
	qcom,mdss-dsi-t-clk-pre = <0x30>;
	qcom,mdss-dsi-display-timings {
		timing@0 {
			qcom,mdss-dsi-panel-phy-timings = [00 1f 08 08 24 23 08
				08 05 03 04 00];
			qcom,display-topology = <2 0 2>,
				<1 0 2>;
			qcom,default-topology-index = <0>;
		};
	};
};

&dsi_nubia_jdi_s6d1ha2a01_cmd {
        qcom,mdss-dsi-t-clk-post = <0x0c>;
        qcom,mdss-dsi-t-clk-pre = <0x29>;
        qcom,mdss-dsi-display-timings {
                timing@0{
                        qcom,mdss-dsi-panel-phy-timings = [00 1A 06 06 22 20 07
                                07 04 03 04 00];
                        qcom,display-topology = <1 0 1>;
                        qcom,default-topology-index = <0>;
                };
        };
};


&dsi_nubia_jdi_s6d1ha2a01_cmd {
				qcom,panel-supply-entries = <&nubia_dsi_panel_pwr_supply>;
				qcom,mdss-dsi-bl-pmic-control-type = "bl_ctrl_wled";
				qcom,mdss-brightness-max-level = <4095>;
				qcom,mdss-dsi-bl-min-level = <25>;
				qcom,mdss-dsi-bl-max-level = <4095>;
				qcom,mdss-dsi-mode-sel-gpio-state = "single_port";
				qcom,platform-reset-gpio = <&tlmm 6 0>;
				qcom,platform-te-gpio = <&tlmm 10 0>;
};

&dsi_jdi_td4310_1080_2160_5p99_video{
				qcom,panel-supply-entries = <&dsi_panel_pwr_supply>;

                                qcom,mdss-dsi-bl-pmic-control-type = "bl_ctrl_wled";
                                qcom,mdss-brightness-max-level = <4095>;
                                qcom,mdss-dsi-bl-min-level = <15>;
                                qcom,mdss-dsi-bl-max-level = <4095>;
                                qcom,mdss-dsi-mode-sel-gpio-state = "single_port";
                                qcom,platform-reset-gpio = <&tlmm 6 0>;
};


&dsi_nubia_boe_himax_cmd{
				qcom,panel-supply-entries = <&nubia_dsi_panel_pwr_supply_boe>;
				qcom,sub-panel-supply-entries = <&nubia_dsi_panel_pwr_supply_boe_sub>;

				qcom,mdss-dsi-bl-pmic-control-type = "bl_ctrl_wled";
				qcom,mdss-brightness-max-level = <4095>;
				qcom,mdss-dsi-bl-min-level = <15>;
				qcom,mdss-dsi-bl-max-level = <4095>;
				qcom,mdss-dsi-mode-sel-gpio-state = "single_port";
				qcom,platform-reset-gpio = <&tlmm 6 0>;
				qcom,platform-sub-lcd-reset-gpio = <&tlmm 7 0>;
				qcom,platform-te-gpio = <&tlmm 10 0>;
				qcom,platform-lcd-switch-en-gpio = <&tlmm 29 0>;
				qcom,platform-lcd-switch-gpio = <&tlmm 39 0>;
				qcom,platform-sub-lcd-power-1p8-gpio = <&tlmm 35 0>;
				qcom,platform-sub-tp-reset-gpio = <&tlmm 99 0>;
				qcom,platform-sub-lcd-fd-gpio = <&tlmm 95 0>;

};

